# CEC1734_S0_2HW register map
Vendor: Microchip Technology; Series: CEC; File version: 0
CPU: CM4 r1p0, little endian, MPU, FPU, 3 interrupt priority bits, 196 interrupts
Registers are 32-bit, read-write, reset 0x0 unless marked. A register's access mark holds for its fields unless they carry their own. Offsets are from the block's base; [hi:lo] are bit positions; {n}, {i} and the like mark numbered series.

## TFDP — The TFDP serially transmits EC-originated diagnostic vectors to an external debug trace system.
Base 0x40008C00; register names take the prefix TFDP_
0x00 MSDATA 8-bit — Debug data to be shifted out on the TFDP Debug port. While data is being shifted out, the Host Interface will 'hold-off' additional writes to the data register until the transfer is complete.
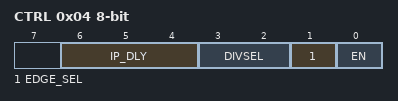
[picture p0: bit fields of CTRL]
0x04 CTRL 8-bit — Debug Control Register
  [6:4] IP_DLY — Inter-packet Delay. The delay is in terms of TFDP Debug output clocks.
  [3:2] DIVSEL — Clock Divider Select.
  [1] EDGE_SEL — 1= Data is shifted out on the falling edge of the debug clock, 0= Data is shifted out on the rising edge of the debug clock (Default)
  [0] EN — Enable. 1=Clock enabled, 0=Clock is disabled (Default)

## VTR_REG_BANK — The VBAT Register Bank block is a block implemented for miscellaneous battery-backed registers.
Base 0x4000A400; register names take the prefix VTR_REG_BANK_
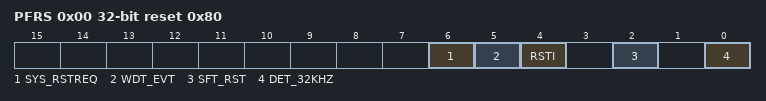
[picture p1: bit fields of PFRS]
0x00 PFRS reset 0x80 — The Power-Fail and Reset Status Register collects and retains the VBAT RST and WDT event status when VCC1 is unpowered.
  [6] SYS_RSTREQ — This bit is set to '1b' if a RESET_SYS was triggered by an ARM SYSRESETREQ event. This bit is cleared to '0b' when written with a '1b'; writes of a '0b' have no effect. (R/WC)
  [5] WDT_EVT — This bit is set to '1b' if a RESET_SYS was triggered by a Watchdog Timer event. This bit is cleared to '0b' when written with a '1b'; writes of a '0b' have no effect. (R/WC)
  [4] RSTI — This bit is set to '1b' if a RESET_SYS was triggered by a low signal on the RESETI# input pin. This bit is cleared to '0b' when written with a '1b'; writes of a '0b' have no effect. (R/WC)
  [2] SFT_RST — This bit is set to '1b' if a was triggered by an assertion of the SOFT_SYS_RESET bit in the System Reset Register. This bit is cleared to '0b' when written with a '1b'; writes of a '0b' have no effect. (R/WC)
  [0] DET_32KHZ — Detect 32KHz Clock Input (R/WC)

## OTP — OTP Programming registers.
Base 0x40082000; register names take the prefix OTP_
{0x44+i} WR_LOCK{i} 8-bit (i=0..3) — This is the Write Lock Register.
  [7:0] WL{i} — When any of the bits are set, the corresponding 32byte range in the OTP is not writable.
{0x48+i} RD_LOCK{i} 8-bit (i=0..3) — This is the Read Lock Register.
  [7:0] RL{i} — When any of the bits are set, the corresponding 32byte range in the OTP is not readable.
0x4C WR_FINE_LCK — This is the Write Fine Lock Register.
  [31:0] WR_FINE_LCK — Each bit locks write to a byte in the OTP range starting byte 320 to 351 0=Not Locked 1=Locked.
0x50 RD_FINE_LCK — This is the Read Fine Lock Register.
  [31:0] RD_FINE_LCK — Each bit locks read to a byte in the OTP range starting byte 320 to 351 0=Not Locked 1=Locked.

## FPU — Floating Point Unit
Base 0xE000EF30; register names take the prefix FPU_
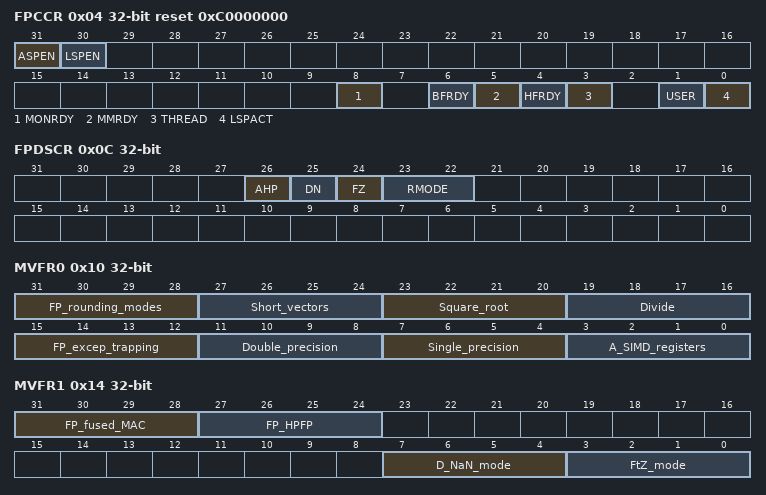
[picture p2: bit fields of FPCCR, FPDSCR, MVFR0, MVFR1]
0x04 FPCCR reset 0xC0000000 — Floating-Point Context Control Register
  [31] ASPEN, [30] LSPEN, [8] MONRDY, [6] BFRDY, [5] MMRDY, [4] HFRDY, [3] THREAD, [1] USER, [0] LSPACT
0x08 FPCAR — Floating-Point Context Address Register
  [31:3] ADDRESS — Address for FP registers in exception stack frame
0x0C FPDSCR — Floating-Point Default Status Control Register
  [26] AHP — Default value for FPSCR.AHP
  [25] DN — Default value for FPSCR.DN
  [24] FZ — Default value for FPSCR.FZ
  [23:22] RMODE — Default value for FPSCR.RMODE
    0=RN (Round to Nearest); 1=RP (Round towards Positive Infinity); 2=RM (Round towards Negative Infinity); 3=RZ (Round towards Zero)
0x10 MVFR0 ro — Media and FP Feature Register 0
  [31:28] FP_rounding_modes, [27:24] Short_vectors, [23:20] Square_root, [19:16] Divide, [15:12] FP_excep_trapping, [11:8] Double_precision, [7:4] Single_precision, [3:0] A_SIMD_registers
0x14 MVFR1 ro — Media and FP Feature Register 1
  [31:28] FP_fused_MAC, [27:24] FP_HPFP, [7:4] D_NaN_mode, [3:0] FtZ_mode

## Notices in the file
Copyright (c) 2023 Microchip Technology Inc.
SPDX-License-Identifier: Apache-2.0
Licensed under the Apache License, Version 2.0 (the "License");
you may not use this file except in compliance with the License.
You may obtain a copy of the License at
http://www.apache.org/licenses/LICENSE-2.0
Unless required by applicable law or agreed to in writing, software
distributed under the License is distributed on an "AS IS" BASIS,
WITHOUT WARRANTIES OR CONDITIONS OF ANY KIND, either express or implied.
See the License for the specific language governing permissions and
limitations under the License.
